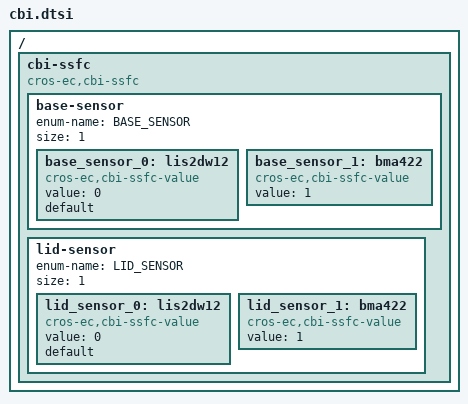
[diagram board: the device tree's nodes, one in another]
/* Copyright 2025 The ChromiumOS Authors
 * Use of this source code is governed by a BSD-style license that can be
 * found in the LICENSE file.
 */

/ {
	cbi-ssfc {
		compatible = "cros-ec,cbi-ssfc";
		/*
		 * SSFC field to identify BASE motion sensor.
		 */
		base-sensor {
			enum-name = "BASE_SENSOR";
			size = <1>;
			base_sensor_0: lis2dw12 {
				compatible = "cros-ec,cbi-ssfc-value";
				status = "okay";
				value = <0>;
				default;
			};
			base_sensor_1: bma422 {
				compatible = "cros-ec,cbi-ssfc-value";
				status = "okay";
				value = <1>;
			};
		};
		/*
		 * SSFC field to identify LID motion sensor.
		 */
		lid-sensor {
			enum-name = "LID_SENSOR";
			size = <1>;
			lid_sensor_0: lis2dw12 {
				compatible = "cros-ec,cbi-ssfc-value";
				status = "okay";
				value = <0>;
				default;
			};
			lid_sensor_1: bma422 {
				compatible = "cros-ec,cbi-ssfc-value";
				status = "okay";
				value = <1>;
			};
		};
	};
};
